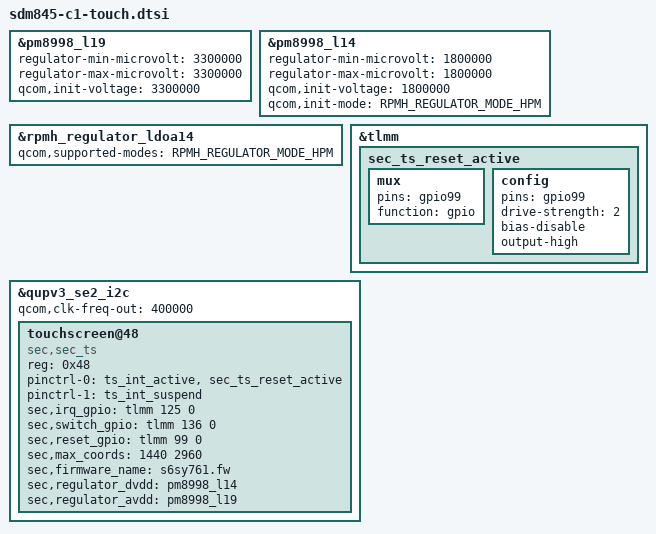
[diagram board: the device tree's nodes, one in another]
/* Copyright (c) 2017 Google, Inc.
 *
 * This software is licensed under the terms of the GNU General Public
 * License version 2, as published by the Free Software Foundation, and
 * may be copied, distributed, and modified under those terms.
 *
 * This program is distributed in the hope that it will be useful,
 * but WITHOUT ANY WARRANTY; without even the implied warranty of
 * MERCHANTABILITY or FITNESS FOR A PARTICULAR PURPOSE.  See the
 * GNU General Public License for more details.
 *
 */

/* VDDI = 1.8v, AVDD = 3.0v ~ 3.3v */
&pm8998_l19 {
	regulator-min-microvolt = <3300000>;
	regulator-max-microvolt = <3300000>;
	qcom,init-voltage = <3300000>;
	status = "okay";
};

&pm8998_l14 {
	regulator-min-microvolt = <1800000>;
	regulator-max-microvolt = <1800000>;
	qcom,init-voltage = <1800000>;
	qcom,init-mode = <RPMH_REGULATOR_MODE_HPM>;
	status = "okay";
};

&rpmh_regulator_ldoa14 {
	qcom,supported-modes = <RPMH_REGULATOR_MODE_HPM>;
};

&tlmm {
	sec_ts_reset_active: sec_ts_reset_active {
		mux {
				pins = "gpio99";
				function = "gpio";
		};
		config {
				pins = "gpio99";
				drive-strength = <2>;
				bias-disable;
				output-high;
		};
	};
};

/* AP Touch I2C SDA is gpio27, SCL is gpio28. (QUP2)
 * Reset gpio99, int gpio125.
 */

&qupv3_se2_i2c {
	status = "ok";
	qcom,clk-freq-out = <400000>;

	touchscreen@48 {
		status = "ok";
		compatible = "sec,sec_ts";
		reg = <0x48>;
		pinctrl-names = "on_state", "off_state";
		pinctrl-0 = <&ts_int_active &sec_ts_reset_active>;
		pinctrl-1 = <&ts_int_suspend>;

		sec,irq_gpio = <&tlmm 125 0>;	/* required */
		sec,switch_gpio = <&tlmm 136 0>;
		sec,reset_gpio = <&tlmm 99 0>;
		//sec,irq_type = ?;		/* optional - IRQF flags - default is IRQF_TRIGGER_LOW | IRQF_ONESHOT */
		sec,max_coords = <1440 2960>;
		sec,firmware_name = "s6sy761.fw";
		sec,regulator_dvdd = "pm8998_l14";	/* required */
		sec,regulator_avdd = "pm8998_l19";
	};
};
